# nrf5340_application register map
Vendor: Nordic Semiconductor; Series: nrf53; File version: 1
CPU: CM33 r0p4, little endian, MPU, FPU, 3 interrupt priority bits, 69 interrupts
Registers are 32-bit, read-write, reset 0x0 unless marked. A register's access mark holds for its fields unless they carry their own. Offsets are from the block's base; [hi:lo] are bit positions; {n}, {i} and the like mark numbered series.

## CC_PKA_S — CRYPTOCELL PKA engine
Base 0x50845000; alternate view of CC_AES_S
{0x0+4i} MEMORY_MAP[{i}] (i=0..31) — Description collection: Register for mapping the virtual register R[n] to a physical address in the PKA SRAM.
  [10:1] ADDR — The physical word address used for the virtual register.
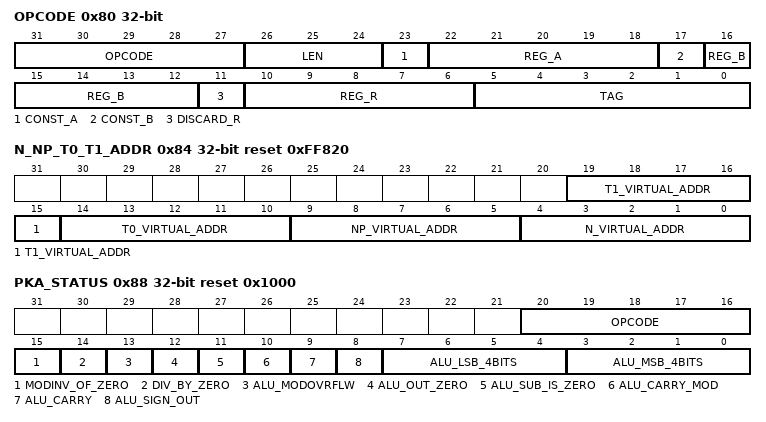
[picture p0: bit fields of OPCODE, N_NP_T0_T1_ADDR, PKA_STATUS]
0x80 OPCODE — Operation code to be executed by the PKA engine. Writing to this register triggers the PKA operation.
  [31:27] OPCODE — Operation code to be executed by the PKA engine
    0=Terminate operation; 4=AddInc (Add or Increment); 5=SubDecNeg (Subtract, Decrement, or Negate); 6=ModAddInc (Modular Add or Modular Increment); 7=ModSubDecNeg (Modular Subtract, Modular Decrement, or Modular Negate); 8=ANDTST0CLR0 (Perform AND, test, or clear); 9=ORCOPYSET0 (Perform OR, copy, or set bits); 10=XORFLP0INVCMP (Perform XOR, flip bits, invert, or compare); 12=SHR0 (Shift right 0 operation); 13=SHR1 (Shift right 1 operation); 14=SHL0 (Shift left 0 operation); 15=SHL1 (Shift left 1 operation); 16=MulLow (Multiply low operation); 17=ModMul (Modular multiply operation); 18=ModMulN (Modular multiply N operation); 19=ModExp (Modular exponentiation operation); 20=Division operation; 21=ModInv (Modular inversion operation); 22=ModDiv (Modular division operation); 23=MulHigh (Multiply high operation); 24=ModMLAC (Modular multiplication acceleration); 25=ModMLACNR (Modular multiplication acceleration where final reduction is omitted); 27=Reduction operation
  [26:24] LEN — The length of the operands. This value serves as an PKA length register index. E.g.: if LEN field value is set to 0, PKA_L[0] holds the size of the operands.
  [23] CONST_A — This field controls the interpretation of REG_A.
    0=Register (REG_A is intepreted as a register index.); 1=Constant (REG_A is intepreted as a constant.)
  [22:18] REG_A — Operand A virtual register index.
  [17] CONST_B — This field controls the interpretation of REG_B.
    0=Register (REG_B is intepreted as a register index.); 1=Constant (REG_B is intepreted as a constant.)
  [16:12] REG_B — Operand B virtual register index.
  [11] DISCARD_R — This field controls the interpretation of REG_R.
    0=Register (REG_R is intepreted as a register index.); 1=Discard (Result is discarded.)
  [10:6] REG_R — Result register virtual register index.
  [5:0] TAG — Holds the operation tag or the operand C virtual register index.
0x84 N_NP_T0_T1_ADDR reset 0xFF820 — This register defines the N, Np, T0, and T1 virtual register index.
  [19:15] T1_VIRTUAL_ADDR — Temporary register 1 virtual register index. Default is R31.
  [14:10] T0_VIRTUAL_ADDR — Temporary register 0 virtual register index. Default is R30.
  [9:5] NP_VIRTUAL_ADDR — Register Np virtual register index. Default is R1.
  [4:0] N_VIRTUAL_ADDR — Register N virtual register index. Default is R0.
0x88 PKA_STATUS ro reset 0x1000 — This register holds the status for the PKA pipeline.
  [20:16] OPCODE — Opcode of the last operation
  [15] MODINV_OF_ZERO — Indicates the modular inverse of zero.
  [14] DIV_BY_ZERO — Indication if the division is done by zero.
  [13] ALU_MODOVRFLW — Modular overflow flag.
  [12] ALU_OUT_ZERO — Indicates if the result of ALU OUT is zero.
  [11] ALU_SUB_IS_ZERO — Indicates the last subtraction operation sign.
  [10] ALU_CARRY_MOD — Holds the carry of the last modular operation.
  [9] ALU_CARRY — Holds the carry of the last ALU operation.
  [8] ALU_SIGN_OUT — Indicates the MSB sign of the last operation.
  [7:4] ALU_LSB_4BITS — The least significant 4-bits of the operand updated in shift operation.
  [3:0] ALU_MSB_4BITS — The most significant 4-bits of the operand updated in shift operation.
0x8C PKA_SW_RESET wo — Reset the PKA engine.
  [0] RESET — Writing any value to this address resets the PKA engine. The reset takes 4 CPU clock cycles to complete.
    1=Enable (Reset PKA engine.)
{0x90+4i} PKA_L[{i}] (i=0..7) — Description collection: This register holds the operands bit size.
  [12:0] OpSize — Operand bit size.
0xB0 PKA_PIPE ro reset 0x1 — Status register indicating if the PKA pipeline is ready to receive a new OPCODE.
  [0] STATUS — PKA pipeline status.
    0=NotReady (PKA pipeline is not ready for a new OPCODE); 1=Ready (PKA pipeline is ready for a new OPCODE)
0xB4 PKA_DONE ro reset 0x1 — Status register indicating if the PKA operation has been completed.
  [0] STATUS — PKA operation status.
    0=Processing (PKA operation is processing); 1=Completed (PKA operation is completed and pipeline is empty)
0xC4 PKA_VERSION ro reset 0x16110215 — PKA engine HW version. Reset value holds the version.
0xD4 PKA_SRAM_WADDR wo — Start address in PKA SRAM for subsequent write transactions.
  [31:0] ADDR — PKA SRAM start address for write transaction
0xD8 PKA_SRAM_WDATA wo — Write data to PKA SRAM. Writing to this register triggers a DMA transaction writing data into PKA SRAM. The DMA address offset is automatically incremented during write.
  [31:0] DATA — Data to write to PKA SRAM.
0xDC PKA_SRAM_RDATA ro — Read data from PKA SRAM. Reading from this register triggers a DMA transaction read data from PKA SRAM. The DMA address offset is automatically incremented during read.
  [31:0] DATA — Data to read from PKA SRAM
0xE0 PKA_SRAM_WCLEAR wo — Register for clearing PKA SRAM write buffer.
  [31:0] CLEAR — Clear the PKA SRAM write buffer.
0xE4 PKA_SRAM_RADDR wo — Start address in PKA SRAM for subsequent read transactions.
  [31:0] ADDR — PKA SRAM start address for read transaction
